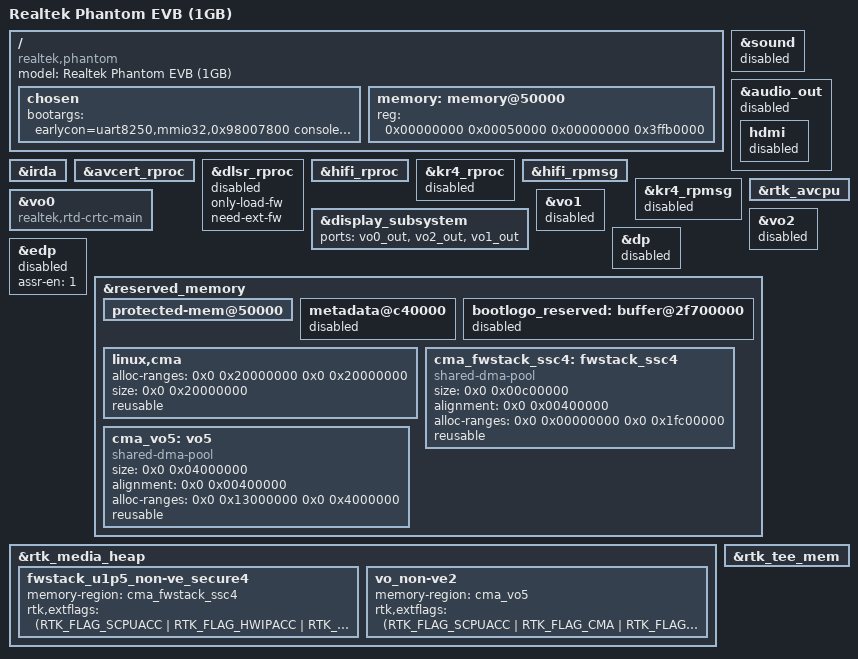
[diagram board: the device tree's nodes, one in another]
// SPDX-License-Identifier: (GPL-2.0-or-later OR BSD-2-Clause)
/*
 * Realtek RTD1501S Phantom EVB
 *
 * Copyright (c) 2024 Realtek Semiconductor Corp.
 */

/dts-v1/;

#include "rtd1501s-phantom.dtsi"

/ {
	compatible = "realtek,phantom", "realtek,rtd1501s";
	model = "Realtek Phantom EVB (1GB)";
	chosen {
		bootargs = "earlycon=uart8250,mmio32,0x98007800 console=ttyS0,460800 8250.nr_uarts=2 init=/init loglevel=8 max_loop=64 loop.max_part=7 firmware_class.path=/vendor/firmware/,/vendor/av_fw";
	};

	memory: memory@50000 {
		device_type = "memory";
		reg = <0x00000000 0x00050000 0x00000000 0x3ffb0000>;
	};
};

&sound {
	status = "disabled";
};

&audio_out {
	status = "disabled";
	hdmi {
		status = "disabled";
	};
};

&irda {
	status = "okay";
};

&avcert_rproc {
	status = "okay";
};

&dlsr_rproc {
	only-load-fw;
	need-ext-fw;
	status = "disabled";
};

&hifi_rproc {
	status = "okay";
};

&kr4_rproc {
	status = "disabled";
};

&hifi_rpmsg {
	status = "okay";
};

&kr4_rpmsg {
	status = "disabled";
};

&rtk_avcpu {
	status = "okay";
};

&display_subsystem {
	status = "okay";
	ports = <&vo0_out>, <&vo2_out>, <&vo1_out>;
};

&vo0 {
	compatible = "realtek,rtd-crtc-main";
	status = "okay";
};

&vo1 {
	status = "disabled";
};

&vo2 {
	status = "disabled";
};

&dp {
	status = "disabled";
};

&edp {
	status = "disabled";
	assr-en = <1>;
};

&reserved_memory {
	protected-mem@50000 {
		status = "okay";
	};

	metadata@c40000 {
		status = "disabled";
	};

	bootlogo_reserved: buffer@2f700000 {
		status = "disabled";
	};

	linux,cma {
		alloc-ranges=<0x0 0x20000000 0x0 0x20000000>;
		size = <0x0 0x20000000>; /* 512M */
		reusable;
	};

	cma_fwstack_ssc4:fwstack_ssc4 {
		compatible = "shared-dma-pool";
		size = <0x0 0x00c00000>;		    /* 12M */
		alignment = <0x0 0x00400000>;

		/* Avoid crossing A/VCPU PA2VA per 512M boundary */
		/* Avoid allocating 0x1fc00000 ~ 0x1fc00fff to LX CPU (A/VCPU/VE3) */
		alloc-ranges=<0x0 0x00000000 0x0 0x1fc00000>;
		reusable;
	};

	cma_vo5:vo5 {
		compatible = "shared-dma-pool";
		size = <0x0 0x04000000>;            /* 64M */
		alignment = <0x0 0x00400000>;
		alloc-ranges=<0x0 0x13000000 0x0 0x4000000>;
		reusable;
	};

	/delete-node/linux,cma_1;
	/delete-node/linux,cma_2;
	/delete-node/bootlogo_reserved;
};

&rtk_media_heap {
	fwstack_u1p5_non-ve_secure4 {
		memory-region = <&cma_fwstack_ssc4>;
		rtk,extflags = < (RTK_FLAG_SCPUACC |
		RTK_FLAG_HWIPACC | RTK_FLAG_CMA | RTK_FLAG_VCPU_FWACC |
		RTK_FLAG_ACPUACC | RTK_FLAG_PROTECTED_V2_FW_STACK) >;
	};

	vo_non-ve2 {
		memory-region = <&cma_vo5>;
		rtk,extflags = < (RTK_FLAG_SCPUACC |
		RTK_FLAG_CMA |
		RTK_FLAG_SUPPORT_NONCACHED |
		RTK_FLAG_SKIP_ZERO) >;
	};

};

&rtk_tee_mem {
	status = "okay";
};
